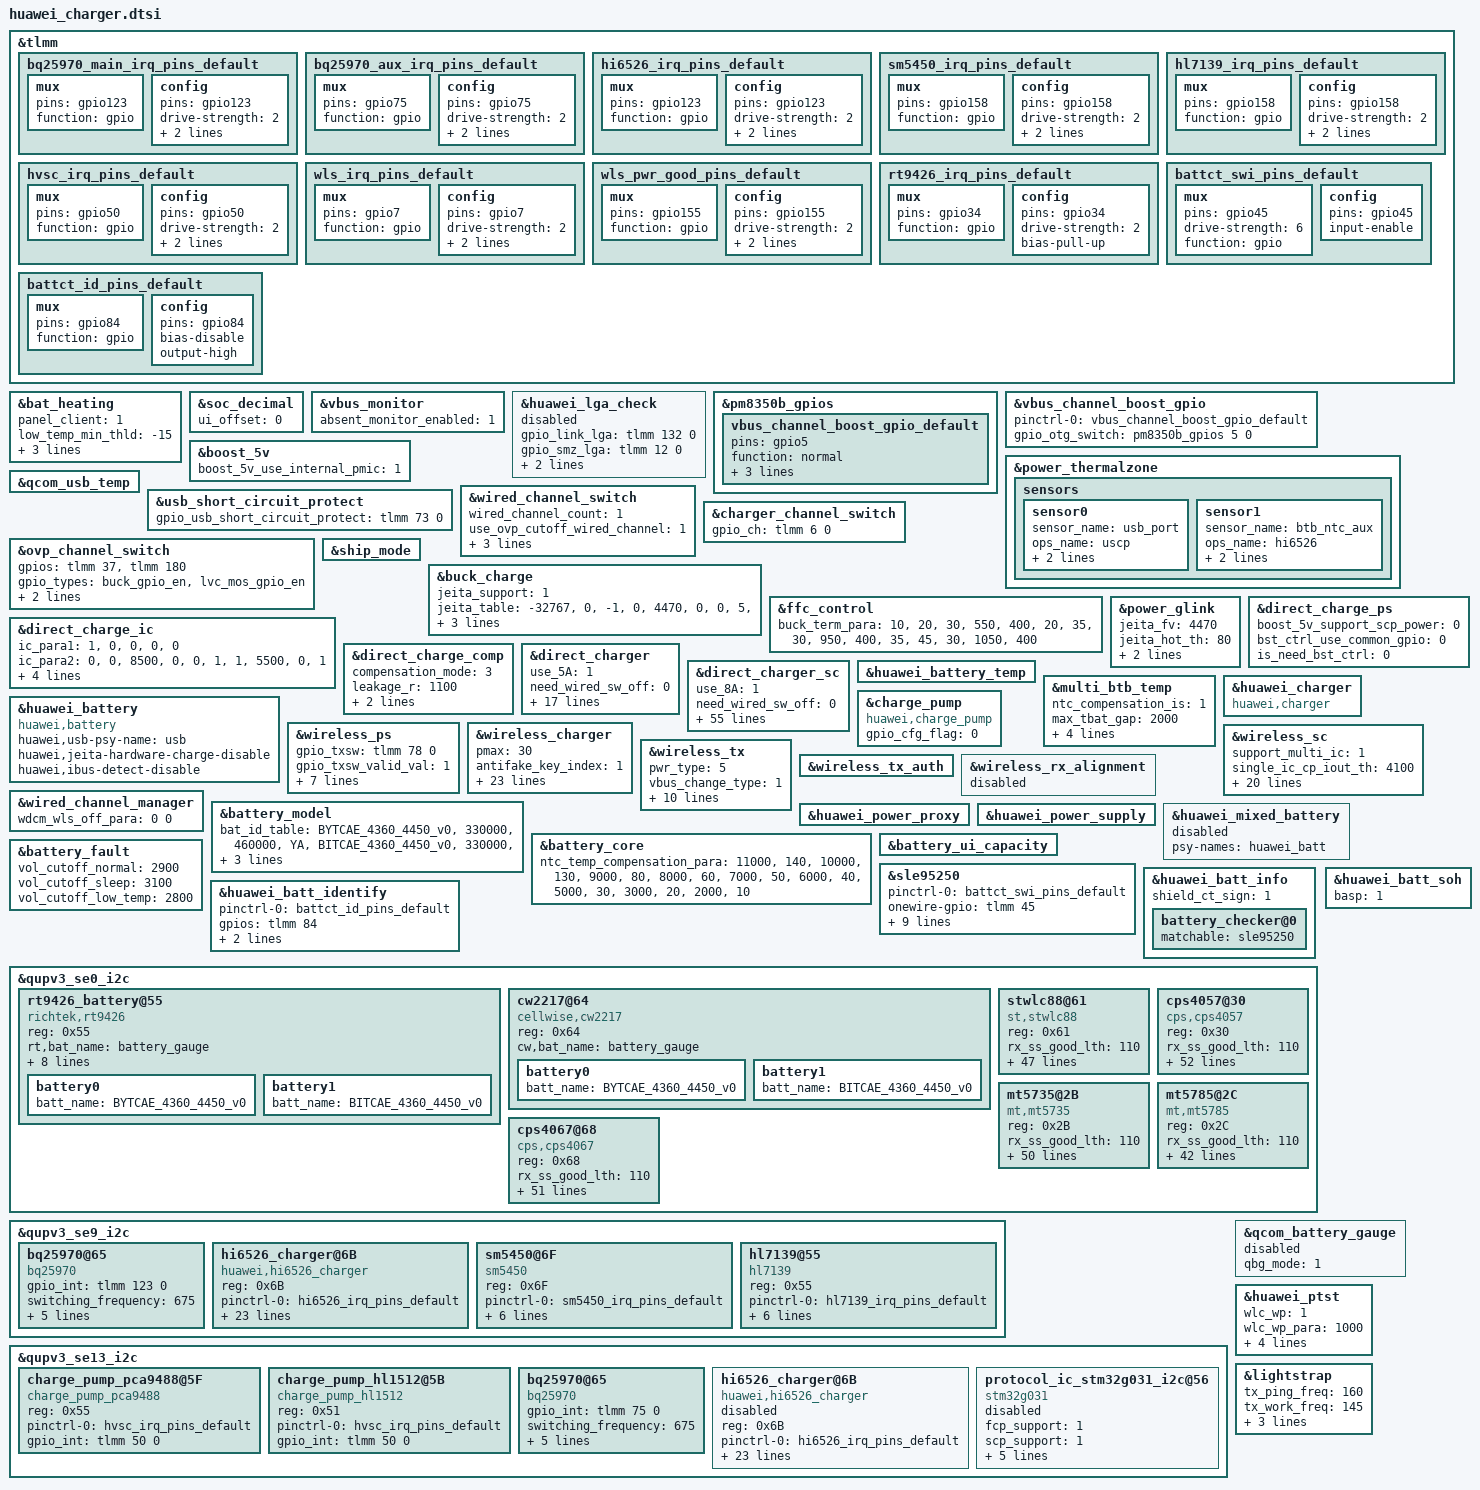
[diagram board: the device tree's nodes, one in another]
&tlmm {
	bq25970_main_irq_pins_default: bq25970_main_irq_pins_default {
		mux {
			pins = "gpio123";
			function = "gpio";
		};
		config {
			pins = "gpio123";
			drive-strength = <2>;
			bias-pull-up;
			input-enable;
		};
	};

	bq25970_aux_irq_pins_default: bq25970_aux_irq_pins_default {
		mux {
			pins = "gpio75";
			function = "gpio";
		};
		config {
			pins = "gpio75";
			drive-strength = <2>;
			bias-pull-up;
			input-enable;
		};
	};

	hi6526_irq_pins_default: hi6526_irq_pins_default {
		mux {
			pins = "gpio123";
			function = "gpio";
		};
		config {
			pins = "gpio123";
			drive-strength = <2>;
			bias-pull-up;
			input-enable;
		};
	};

	sm5450_irq_pins_default: sm5450_irq_pins_default {
		mux {
			pins = "gpio158";
			function = "gpio";
		};
		config {
			pins = "gpio158";
			drive-strength = <2>;
			bias-pull-up;
			input-enable;
		};
	};

	hl7139_irq_pins_default: hl7139_irq_pins_default {
		mux {
			pins = "gpio158";
			function = "gpio";
		};
		config {
			pins = "gpio158";
			drive-strength = <2>;
			bias-pull-up;
			input-enable;
		};
	};

	hvsc_irq_pins_default: hvsc_irq_pins_default {
		mux {
			pins = "gpio50";
			function = "gpio";
		};
		config {
			pins = "gpio50";
			drive-strength = <2>;
			bias-pull-up;
			input-enable;
		};
	};

	wls_irq_pins_default: wls_irq_pins_default {
		mux {
			pins = "gpio7";
			function = "gpio";
		};
		config {
			pins = "gpio7";
			drive-strength = <2>;
			bias-pull-up;
			input-enable;
		};
	};

	wls_pwr_good_pins_default: wls_pwr_good_pins_default {
		mux {
			pins = "gpio155";
			function = "gpio";
		};
		config {
			pins = "gpio155";
			drive-strength = <2>;
			bias-pull-down;
			input-enable;
		};
	};


	rt9426_irq_pins_default: rt9426_irq_pins_default {
		mux {
			pins = "gpio34";
			function = "gpio";
		};
		config {
			pins = "gpio34";
			drive-strength = <2>;
			bias-pull-up;
		};
	};

	battct_swi_pins_default: battct_swi_pins_default {
		mux {
			pins = "gpio45";
			drive-strength = <6>;
			function = "gpio";
		};
		config {
			pins = "gpio45";
			input-enable;
		};
	};

	battct_id_pins_default: battct_id_pins_default {
		mux {
			pins = "gpio84";
			function = "gpio";
		};
		config {
			pins = "gpio84";
			bias-disable;
			output-high;
		};
	};
};

&bat_heating {
	panel_client = "1";
	low_temp_min_thld = "-15";
	low_temp_min_ibat = "-550";
	temp_para =
		"-32767", "0", "0",
		"0", "5", "0",
		"5", "10", "400",
		"10", "20", "2500",
		"20", "45", "4500",
		"45", "32767", "0";
	status = "ok";
};

&soc_decimal {
	ui_offset = <0>;
	status = "ok";
};

&vbus_monitor {
	status = "ok";
	absent_monitor_enabled = <1>;
};

&huawei_lga_check {
	gpio_link_lga = <&tlmm 132 0>; /* GPIO_132 */
	gpio_smz_lga = <&tlmm 12 0>; /* GPIO_012 */
	/* type, name, abnormal_threshold, dmd_no, dmd_switch */
	check_para =
		"2", "gpio_link_lga", "1", "920004103", "1",
		"2", "gpio_smz_lga", "1", "920004103", "1";
	status = "disabled";
};

&pm8350b_gpios {
	vbus_channel_boost_gpio_default: vbus_channel_boost_gpio_default {
		pins = "gpio5";
		function = "normal"; /* normal output */
		bias-disable;
		power-source = <0>; /* VIN0 */
		output-low; /* digital output, no invert */
	};
};

&vbus_channel_boost_gpio {
	pinctrl-names = "vbus_channel_boost_gpio_default";
	pinctrl-0 = <&vbus_channel_boost_gpio_default>;
	gpio_otg_switch = <&pm8350b_gpios 5 0>; /* PM8350B_005 */
	status = "ok";
};

&boost_5v {
	boost_5v_use_internal_pmic = <1>;
	status = "ok";
};

&power_thermalzone {
	status = "ok";
	sensors{
		sensor0 {
			sensor_name = "usb_port";
			ops_name = "uscp";
			adc_channel = <0>;
			ntc_index = <5>;
		};
		sensor1 {
			sensor_name = "btb_ntc_aux";
			ops_name = "hi6526";
			adc_channel = <0>;
			ntc_index = <5>;
		};
	};
};

&qcom_usb_temp {
	status = "ok";
};

&usb_short_circuit_protect {
	gpio_usb_short_circuit_protect = <&tlmm 73 0>; /* GPIO_073 */
	status = "ok";
};

&wired_channel_switch {
	wired_channel_count = <1>;
	use_ovp_cutoff_wired_channel = <1>;
	use_super_switch_cutoff_wired_channel = <0>;
	use_wireless_switch_cutoff_wired_channel = <0>;
	wired_sw_dflt_on = <1>;
	status = "ok";
};

&ovp_channel_switch {
	gpios = <&tlmm 37 0 &tlmm 180 0>;
	gpio_types = "buck_gpio_en", "lvc_mos_gpio_en";
	gpio_en_status = <0 1>;
	gpio_low_by_set_input = <0>;
	status = "ok";
};

&charger_channel_switch {
	gpio_ch = <&tlmm 6 0>; /* GPIO_006 */
	status = "ok";
};

&ship_mode {
	status = "ok";
};

&buck_charge {
	jeita_support = <1>;
	jeita_table =
		"-32767", "0", "-1","0","4470","0",
		"0", "5", "-1", "390", "4470", "0",
		"5", "10", "-1", "1170", "4470", "3",
		"10", "45", "-1", "3000", "4470", "3",
		"45", "50", "-1", "1365", "4100", "3",
		"50", "32767", "-1", "0", "4100", "0";
	status = "ok";
};

&ffc_control {
	status = "ok";
	buck_term_para =
		"10", "20", "30", "550", "400",
		"20", "35", "30", "950", "400",
		"35", "45", "30", "1050", "400";
};

&power_glink {
	jeita_fv = <4470>;
	jeita_hot_th = <80>;
	adsp_jeita_table = <
		0 5 390 4470
		5 10 1170 4470
		10 70 3000 4470
		70 80 1365 4100
	>;
};

&direct_charge_ps {
	boost_5v_support_scp_power = <0>;
	bst_ctrl_use_common_gpio = <0>;
	is_need_bst_ctrl = <0>;
	status = "ok";
};

&direct_charge_ic {
	/* The IC_PARA table is used to find the relationship between chip and path */
	/* the chip's current passing capacity */
	/* and the sampling points of battery voltage and current */
	/* ic_index path_index max_ibat ibat_sample_point vbat_sample_point */
	ic_para1 =
		"1", "0", "0", "0", "0";
	ic_para2 =
		"0", "0", "8500", "0", "0",
		"1", "1", "5500", "0", "1";
	mode_para =
		"lvc_mode", "ic_para1",
		"sc_mode", "ic_para2";
	vbat_en_gpio_output_value = <0>;
	vbat_en_gpio = <&tlmm 98 0>;
	status = "ok";
};

&direct_charge_comp {
	compensation_mode = <3>;
	leakage_r = <1100>;
	compensate_r = <7>;
	/* The vbat_samp_point_para table is used to find the comp relationship between chips */
	/* Calculate all compensation values of the same index */
	/* as the final compensation of the chip */
	/* Separately calculate positive and negative poles */
	/* ic_index  p_index  n_index */
	vbat_samp_point_para =
		"0", "0", "0",
		"1", "1", "1";
	status = "ok";
};

&direct_charger {
	use_5A = <1>;
	need_wired_sw_off = <0>;
	need_check_tx_iin = <1>;
	lvc_mos_para = <1 1600 1500>;
	lvc_mos_err_info = <3 3>;
	volt_para =
		"4080", "5000", "4650",
		"4230", "4650", "2800",
		"4400", "2800", "1200";
	vbat_comp_para =
		"default", "50", "0";
	compensate_r = <0>;
	cc_cable_detect_enable = <1>;
	full_path_res_max = <220>;
	scp_work_on_charger = <1>;
	standard_cable_full_path_res_max = <260>;
	first_cc_stage_timer_in_min = <5>;
	stage_need_to_jump = "1";
	low_temp_hysteresis = <5>;
	temp_para =
		"-32767", "10", "0",
		"10", "45", "5000",
		"45", "32767", "0";
	rt_test_para =
		"2000", "105"; /* rt_curr_th rt_test_time */
	status = "ok";
};

&direct_charger_sc {
	use_8A = <1>;
	need_wired_sw_off = <0>;
	dc_volt_ratio = <2>;
	init_delt_vset = <450>;
	max_adaptor_vset = <11000>;
	init_adapter_vset = <8800>;
	vol_err_th = <500>;
	need_check_tx_iin = <1>;
	adaptor_leakage_current_th = <600>;
	vstep = <20>;
	min_dc_bat_vol = <3450>;
	max_dc_bat_vol = <4380>;
	max_current_for_none_standard_cable = <6000>;
	adaptor_antifake_check_enable = <1>;
	adaptor_antifake_key_index = <2>;
	support_multi_ic = <1>;
	multi_ic_ibat_th = <4000>;
	second_resist_check_en = <1>;
	ui_max_pwr = <40000>;
	product_max_pwr = <66000>;
	volt_para =
		"4150", "8500", "6400",
		"4250", "6400", "5000",
		"4300", "5000", "4200",
		"4460", "4200", "3000",
		"4490", "3000", "900";
	volt_para1 =
		"4200", "12300", "11000",
		"4250", "11000", "8800",
		"4300", "8800", "6800",
		"4460", "6800", "4600",
		"4490", "4600", "1200";
	volt_para2 =
		"4200", "12300", "11000",
		"4250", "11000", "8800",
		"4300", "8800", "6800",
		"4460", "6800", "4600",
		"4490", "4600", "1300";
	time_para =
		"1600", "6650",
		"620", "6850",
		"365", "8000",
		"90", "10000";
	bat_para =
		"default", "10", "20", "volt_para",
		"default", "20", "45", "volt_para1",
		"CAE", "10", "20", "volt_para",
		"CAE", "20", "35", "volt_para1",
		"CAE", "35", "45", "volt_para2";
	vbat_comp_para =
		"default", "45", "0",
		"bq25970", "44", "19",
		"rt9759", "44", "34";
	vstep_para =
		"2000", "80";
	compensate_r = <0>;
	cc_cable_detect_enable = <1>;
	full_path_res_max = <450>;
	scp_work_on_charger = <1>;
	standard_cable_full_path_res_max = <280>;
	first_cc_stage_timer_in_min = <10>;
	stage_need_to_jump = "-1";
	low_temp_hysteresis = <5>;
	current_ratio =
		"3", "10", "25", "2", "-1",
		"3", "13", "22", "1", "8000",
		"0", "13", "22", "0", "0";
	vbat_error =
		"3", "120", "2", "-1",
		"3", "80", "1", "0";
	temp_para =
		"-32767", "10", "0",
		"10", "46", "12800",
		"46", "32767", "0";
	resist_para =
		"0", "260", "6000",
		"260", "450", "4000";
	std_resist_para =
		"0", "300", "0",
		"300", "450", "4000";
	second_resist_para =
		"0", "180", "0",
		"180", "450", "8000";
	ctc_second_resist_para =
		"0", "250", "0",
		"250", "450", "8000";
	rt_test_para =
		/* first:sc second:mainsc third:auxsc */
		"3000", "105",
		"3000", "105",
		"3000", "105";
	status = "ok";
};

&huawei_battery_temp {
	status = "ok";
};

&multi_btb_temp {
	status = "ok";
	ntc_compensation_is = <1>;
	max_tbat_gap = <2000>;
	comp_para =
		"11000", "14000",
		"10000", "13000",
		"9000", "8000",
		"8000", "6000",
		"7000", "5000",
		"6000", "4000",
		"5000", "3000",
		"3000", "2000",
		"2000", "1000";
	sensor-names =
		"battery_gauge", "comp_para";
};

&huawei_battery {
	compatible = "huawei,battery";
	status = "ok";
	huawei,usb-psy-name = "usb";
	huawei,jeita-hardware-charge-disable;
	huawei,ibus-detect-disable;
};

&huawei_charger {
	compatible = "huawei,charger";
	status = "ok";
};

&charge_pump {
	compatible = "huawei,charge_pump";
	gpio_cfg_flag = <0>;
	status = "ok";
};

&wireless_ps {
	gpio_txsw = <&tlmm 78 0>; /* GPIO_078 */
	gpio_txsw_valid_val = <1>;
	gpio_rxsw = <&tlmm 157 0>; /* GPIO_157 */
	gpio_rxsw_valid_val = <0>;
	gpio_ext_pwr_sw = <&tlmm 76 0>; /* GPIO_076 */
	gpio_ext_pwr_sw_valid_val = <1>;
	tx_ps_ctrl_src = <0>; /* 0:NA 1:tx_chip 2:AP */
	sysfs_en_pwr = <1>; /* 0:null 1:rx_pwr 2:tx_pwr */
	proc_otp_pwr = <1>; /* 0:null 1:rx_pwr 2:tx_pwr */
	status = "ok";
};

&wireless_charger {
	pmax = <30>;
	antifake_key_index = <1>;
	ignore_qval = <1>;
	sample_delay_time = <6000>;
	support_high_pwr_wltx = <1>;
	product_max_pwr = <50000>;
	ui_max_pwr = <27000>;
	rx_iout_min = <150>;
	rx_iout_step = <100>;
	rx_iout_ctrl_para = <
		0   100  200
		100 200  300
		200 300  400
		300 400  500
		400 500  600
		500 600  700
		600 700  800
		700 800  900
		800 9999 1100
	>;
	segment_para = <
		999 999 5000 5500 825
	>;
	interference_para =
		"0x01", "0xfe", "131", "5000", "5500", "825",
		"0x02", "0xfd", "-1",  "-1",   "-1",   "1000";
	plim_para =
		"2", "fan", "yes", "12000", "9900", "1250",
		"3", "vout_err", "yes", "12000", "9900", "1250",
		"6", "thermal", "no", "12000", "9900", "1250";
	rx_mode_para =
		/*This table should be arranged in ascending order of power mode priority*/
		/*mode  tx_vout  tx_iout tx_vset  rx_vset  rx_iset vrect_lth tbatt cable cert  icon time expect_mode*/
		"5W",   "5000",  "475",  "5000",  "5500",  "900",  "4650",   "-1", "-1", "-1", "0", "-1",  "4",
		"7.5W", "9000",  "1400", "9000",  "9900",  "900",  "8000",   "-1", "-1", "-1", "0", "-1",  "2",
		"10W",  "9000",  "2000", "9000",  "9900",  "1000", "9000",   "-1", "-1", "1",  "1", "-1",  "4",
		"SC_2", "12000", "2000", "12000", "9000",  "-1",   "-1",     "45", "-1", "1",  "1", "-1",  "4",
		"SC_4", "15000", "1800", "15000", "9000",  "-1",   "-1",     "46", "-1", "1",  "2", "-1",  "-1";
	status = "ok";
};

&wireless_sc {
	support_multi_ic = <1>;
	single_ic_cp_iout_th = <4100>;
	multi_ic_para = <2000 1000 1500 10000>;
	max_vgap = <250>;
	iout_drop_th = <500>;
	tbat_limit_para = <10 13 46 42>;
	init_para_col = <13>; /* must couple with init_para */
	init_para =
		/* in ratio-descending order
		 * ext_pwr: bit(0): needed by sc chip; bit(1): needed by rx
		 * type   type_name ext_pwr rx_ratio vbatt(lth, hth) vrx      vout_th vdiff  ileak_th vdelt  rx_vmax   vtx
		 */
		   "0x2", "SC_2",   "0",   "1",     "3550", "4442", "9000",  "450",  "300", "100",   "300", "10000",  "12000",
		   "0x4", "SC_4",   "2",   "1",     "3550", "4442", "9000",  "500",  "300", "100",   "300", "20000",  "15000";
	volt_para00 =
		"4459", "1300", "600";
	volt_para01 =
		"4150", "4100", "3300",
		"4250", "3300", "2200",
		"4300", "2200", "1500",
		"4420", "1500", "1000";
	volt_para02 =
		"4250", "5100", "4100",
		"4300", "4100", "3200",
		"4380", "3200", "2600",
		"4442", "2600", "1000";
	bat_para =
		"default", "10", "45", "0x02", "volt_para00",
		"default", "10", "45", "0x04", "volt_para01",
		"CAE", "10", "45", "0x02", "volt_para00",
		"CAE", "10", "20", "0x04", "volt_para01",
		"CAE", "20", "45", "0x04", "volt_para02";
	vbat_comp_para =
		"default", "45", "0",
		"bq25970", "44", "19",
		"rt9759", "44", "34";
	status = "ok";
};

&wireless_tx {
	pwr_type = <5>; /* VBUS_OTG2 */
	vbus_change_type = <1>; /* charger plug change */
	tx_iin_limit = <0 0 0 0 0 0 0 0 0 0 0 0>;
	tx_dc_done_buck_ilim = <300>;
	/* rx_vmin rx_vmax tx_vset tx_lvset tx_hvset tx_pl_th tx_pl_cnt */
	tx_vset_para = <
		4000 6400 5000 3500 11000 0 0 0
	>;
	/* power_supply ping handshake default */
	tx_stage_vset = <5000 5000 5000 5000>;
	tx_cap_mode = <0x3>; /* Bit0:2.5W/5W Bit1:7.5W Bit2:XXW */
	tx_high_pwr_soc = <100>;
	tx_high_pwr_ilim = <1600>;
	/* hi_pwr_vth hi_pwr_ith hi_pwr2_vth hi_pwr2_ith */
	wltx_hi_pwr_th = <9000 4000 9000 4000>;
	hs_timeout_offset = <5000>;
	tx_cap = <
		/* type vout iout extra */
		0x9 5000  825  0
		0xA 9000  1400 0
	>;
	status = "ok";
};

&wireless_tx_auth {
	status = "ok";
};

&wireless_rx_alignment {
	status = "disabled";
};

&wired_channel_manager {
	/* channel_state: 0-restore 1-cutoff force_flag */
	wdcm_wls_off_para = <0 0>;
	status = "ok";
};

&battery_model {
	bat_id_table =
		"BYTCAE_4360_4450_v0", "330000", "460000", "YA",
		"BITCAE_4360_4450_v0", "330000", "460000", "IA";
	design_fcc = <4360>;
	id_adc_channel = <0>; /* useless but necessary for Qcom, set 0 as default */
	status = "ok";
};

&huawei_power_proxy {
	status = "ok";
};

&huawei_power_supply {
	 status = "ok";
};

&huawei_mixed_battery {
	psy-names = "huawei_batt";
	status = "disabled";
};

&battery_core {
	ntc_temp_compensation_para =
		"11000", "140",
		"10000", "130",
		"9000", "80",
		"8000", "60",
		"7000", "50",
		"6000", "40",
		"5000", "30",
		"3000", "20",
		"2000", "10";
	status = "ok";
};

&battery_ui_capacity {
	status = "ok";
};

&battery_fault {
	vol_cutoff_normal = <2900>;
	vol_cutoff_sleep = <3100>;
	vol_cutoff_low_temp = <2800>;
	status = "ok";
};

&sle95250 {
	pinctrl-names = "default";
	pinctrl-0 = <&battct_swi_pins_default>;
	onewire-gpio = <&tlmm 45 0>;
	product_id0 = <1>;
	product_id2 = <3>;
	gpio_sn_mode_val = <0>;
	dip_check = <0>;
	gpio_swi = <45>;
	gpio_id_mode = <84>;
	gpio_swi_drv = <2>;
	tau = /bits/ 8 <0xa>;
	tau_fastboot = <7>;
	status = "ok";
};

&huawei_batt_info {
	status = "ok";
	shield_ct_sign = <1>;
	battery_checker@0 {
		matchable = <&sle95250>;
		status = "ok";
	};
};

&huawei_batt_identify {
	pinctrl-names = "default";
	pinctrl-0 = <&battct_id_pins_default>;
	gpios = <&tlmm 84 0>;
	id_voltage_gpiov = <0 1>;
	id_sn_gpiov = <0 0>;
	status = "ok";
};

&qupv3_se0_i2c {
	#address-cells = <1>;
	#size-cells = <0>;
	status = "ok";
	rt9426_battery@55{
		reg = <0x55>;
		compatible = "richtek,rt9426";
		rt,bat_name = "battery_gauge";
		pinctrl-names = "default";
		pinctrl-0 = <&rt9426_irq_pins_default>;
		rt9426,gpio-intb = <&tlmm 34 0x0>;
		need_reset_version = <9>;
		rt_config_ver = <12>;
		ntc_compensation_is = <1>;
		ntc_temp_compensation_para =
			"11000", "140",
			"10000", "130",
			"9000", "80",
			"8000", "60",
			"7000", "50",
			"6000", "40",
			"5000", "30",
			"3000", "20",
			"2000", "10";
		status = "ok";
		battery0{
			batt_name = "BYTCAE_4360_4450_v0";
			#include "../../../huawei_charger/rt9426_BYTCAE_4360mAh_4V45_BT231.dtsi"
		};
		battery1{
			batt_name = "BITCAE_4360_4450_v0";
			#include "../../../huawei_charger/rt9426_BITCAE_4360mAh_4V45_BT231.dtsi"
		};
	};

	cw2217@64 {
		compatible = "cellwise,cw2217";
		reg = <0x64>;
		cw,bat_name = "battery_gauge";
		status = "ok";
		battery0{
			batt_name = "BYTCAE_4360_4450_v0";
			#include "../../../huawei_charger/cw2217_1mohm_BYTCAE_4360mAh_4V45_CET_BT231.dtsi"
		};
		battery1{
			batt_name = "BITCAE_4360_4450_v0";
			#include "../../../huawei_charger/cw2217_1mohm_BITCAE_4360mAh_4V45_CET_BT231.dtsi"
		};
	};

	stwlc88@61 {
		compatible = "st,stwlc88";
		reg = <0x61>;
		rx_ss_good_lth = <110>;
		pinctrl-names = "wls_int", "wls_pwr_good";
		pinctrl-0 = <&wls_irq_pins_default>;
		pinctrl-1 = <&wls_pwr_good_pins_default>;
		gpio_int = <&tlmm 7 0>; /* GPIO_007 */
		gpio_en = <&tlmm 77 0>; /* GPIO_077 */
		gpio_en_valid_val = <0>;
		gpio_sleep_en = <&tlmm 189 0>; /* GPIO_189 */
		gpio_pwr_good = <&tlmm 155 0>; /* GPIO_155 */
		mtp_check_delay = <10000>;
		rx_ldo_cfg_5v = /bits/ 8 <0x13 0x13 0x0D 0x03 0x13 0x20 0x2C>;
		rx_ldo_cfg_9v = /bits/ 8 <0x13 0x13 0x0D 0x03 0x13 0x20 0x2C>;
		rx_ldo_cfg_12v = /bits/ 8 <0x13 0x13 0x0D 0x03 0x13 0x20 0x2C>;
		rx_ldo_cfg_sc = /bits/ 8 <0x2F 0x2F 0x0D 0x03 0x13 0x20 0x2C>;
		rx_ploss_th0 = /bits/ 8 <0x20 0x32 0x4A 0x55 0x64 0x00 0x00 0x00 0x00 0x00 0x00 0x1C 0x1A 0x1A 0x1A 0x1A 0x1A 0x88>;
		rx_ploss_th1 = /bits/ 8 <0x3D 0x65 0x73 0x82 0x96 0x00 0x00 0x00 0xE6 0x00 0x00 0x0C 0x06 0x82 0x82 0xF4 0xF0 0x88>;
		rx_ploss_th2 = /bits/ 8 <0x3D 0x65 0x73 0x82 0x96 0x00 0x00 0x00 0x00 0x00 0x00 0x0C 0x06 0x0C 0xFF 0xF4 0xF0 0x88>;
		rx_ploss_th3 = /bits/ 8 <0x1E 0x3C 0x82 0x00 0x00 0x00 0x00 0x0E 0x21 0x22 0x2B 0x9C 0x00 0x00 0x00 0x00 0x00 0x00>;
		rx_ploss_th4 = /bits/ 8 <0x5A 0x79 0xA8 0xBE 0xFA 0x00 0x00 0x00 0x00 0x00 0x00 0x19 0x3B 0x42 0x13 0xA0 0x87 0x88>;
		rx_fod_cond =
			/* This table should be arranged in descending order of strictness */
			/* id  rx_scn  tx_type  vfc */
			"0", "-1", "-1", "5000",
			"1", "-1", "8", "9000",
			"2", "-1", "-1", "9000",
			"3", "-1", "-1", "12000",
			"4", "-1", "-1", "15000";
		tx_fod_para = /bits/ 8 <0x88 0x13 0x88 0x13 0x88 0x13 0x88 0x13 0x64 0x19 0x64 0x19>;
		tx_fod_cnt = <2>;
		temp_para = <
			/* temp(min,max] ilim temp_back */
			0   100       2500 10
			100 999       1500 0
		>;
		time_para = <
			/* time  ilim */
			840   1275
			540   1375
			240   1520
			85    2200
			0     2500
		>;
		tx_high_vctrl =
			"1000", "115", "48", "17000", "18000", "3000",
			"600",  "120", "48", "16000", "17000", "3000",
			"500",  "140", "40", "17000", "16000", "3000",
			"800",  "140", "40", "18000", "17000", "3000";
		tx_time_alarm =
			"0",   "0", "17000", "18000", "0",
			"330", "1", "8000",  "9000", "0";
		tx_tbatt_alarm =
			"0",  "40", "3", "0", "0",    "0",    "0",
			"40", "42", "3", "1", "8000", "9000", "0",
			"42", "99", "0", "1", "5000", "9000", "0";
		tx_fod_alarm =
			"4", "6400", "8000", "3000", "1", "8000", "9000", "0",
			"5", "7200", "9000", "3000", "1", "8000", "9000", "0";
		status = "ok";
	};

	cps4057@30 {
		compatible = "cps,cps4057";
		reg = <0x30>;
		rx_ss_good_lth = <110>;
		pinctrl-names = "wls_int", "wls_pwr_good";
		pinctrl-0 = <&wls_irq_pins_default>;
		pinctrl-1 = <&wls_pwr_good_pins_default>;
		gpio_int = <&tlmm 7 0>; /* GPIO_007 */
		gpio_en = <&tlmm 77 0>; /* GPIO_077 */
		gpio_en_valid_val = <0>;
		gpio_sleep_en = <&tlmm 189 0>; /* GPIO_189 */
		gpio_pwr_good = <&tlmm 155 0>; /* GPIO_155 */
		full_bridge_ith = <200>;
		mtp_check_delay = <10000>;
		rx_mod_cm_cfg = /bits/ 8 <0x7 0x4 0x6>;
		rx_mod_polar_cfg = /bits/ 8 <0x0 0x0 0x0>;
		rx_ldo_cfg_5v = /bits/ 8 <0x32 0x00 0x90 0x01 0x2C 0x01 0x64 0x00>;
		rx_ldo_cfg_9v = /bits/ 8 <0x32 0x00 0x20 0x03 0x2C 0x01 0x64 0x00>;
		rx_ldo_cfg_sc = /bits/ 8 <0x32 0x00 0x20 0x03 0x2C 0x01 0x64 0x00>;
		rx_ploss_th0 = /bits/ 8 <0x00 0x19 0x32 0x4B 0x64 0x7D 0x96 0xAF 0x50 0x05 0x50 0x05 0x50 0x05 0x50 0x05 0x50 0x05 0x50 0x05 0x50 0x05 0x50 0x05>;
		rx_ploss_th1 = /bits/ 8 <0x00 0x19 0x32 0x4B 0x64 0x7D 0x96 0xAF 0x32 0x0A 0x32 0x0A 0x32 0x0A 0x32 0xC8 0x32 0xC8 0x32 0x0A 0x32 0x0A 0x32 0x0A>;
		rx_ploss_th2 = /bits/ 8 <0x00 0x19 0x32 0x4B 0x64 0x7D 0x96 0xAF 0x32 0x0A 0x32 0x0A 0x32 0x0A 0x32 0x0A 0x32 0x0A 0x32 0x0A 0x32 0x0A 0x32 0x0A>;
		rx_ploss_th3 = /bits/ 8 <0x00 0x19 0x32 0x4B 0x64 0x7D 0x96 0xA0 0x28 0x0A 0x28 0x0A 0x28 0x0A 0x28 0x0A 0x28 0x0A 0x28 0x0A 0x28 0x0A 0x28 0x0A>;
		rx_fod_cond =
			/* This table should be arranged in descending order of strictness */
			/* id  rx_scn  tx_type  vfc */
			"0", "-1", "-1", "5000",
			"1", "-1", "8", "9000",
			"2", "-1", "-1", "9000",
			"3", "-1", "-1", "15000";
		tx_ploss_th0 = <5000>; /* 5v full bridge */
		tx_ploss_th1 = <5000>; /* 10v half bridge */
		tx_ploss_th2 = <1000>; /* 10v full bridge low voltage */
		tx_ploss_th3 = <2000>; /* 10v full bridge high voltage */
		tx_hp_ploss_th0 = <3500>; /* 15v full bridge low current */
		tx_hp_ploss_th1 = <5000>; /* 15v full bridge high current */
		tx_ploss_cnt = <3>;
		tx_q_en = <0>;
		tx_q_coil_th = <105>;
		tx_q_th = <50>;
		temp_para = <
		/* temp(min,max] ilim temp_back */
			0   100       2500 10
			100 999       1500 0
		>;
		time_para = <
			/* time  ilim */
			840   1275
			540   1375
			240   1520
			85    2200
			0     2500
		>;
		tx_high_vctrl =
			"1000", "115", "48", "17000", "18000", "3000",
			"600",  "120", "48", "16000", "17000", "3000",
			"500",  "140", "40", "17000", "16000", "3000",
			"800",  "140", "40", "18000", "17000", "3000";
		tx_time_alarm =
			"0",   "0", "17000", "18000", "0",
			"330", "1", "8000",  "9000", "0";
		tx_tbatt_alarm =
			"0",  "40", "3", "0", "0",    "0",    "0",
			"40", "42", "3", "1", "8000", "9000", "0",
			"42", "99", "0", "1", "5000", "9000", "0";
		tx_fod_alarm =
			"4", "6400", "8000",  "3000", "1", "8000", "9000", "0",
			"5", "8000", "10000", "3000", "1", "8000", "9000", "0";
		status = "ok";
	};

	mt5735@2B {
		compatible = "mt,mt5735";
		reg = <0x2B>;
		rx_ss_good_lth = <110>;
		pinctrl-names = "wls_int", "wls_pwr_good";
		pinctrl-0 = <&wls_irq_pins_default>;
		pinctrl-1 = <&wls_pwr_good_pins_default>;
		gpio_int = <&tlmm 7 0>; /* GPIO_007 */
		gpio_en = <&tlmm 77 0>; /* GPIO_077 */
		gpio_en_valid_val = <0>;
		gpio_sleep_en = <&tlmm 189 0>; /* GPIO_189 */
		gpio_pwr_good = <&tlmm 155 0>; /* GPIO_155 */
		full_bridge_ith = <300>;
		mtp_check_delay = <10000>;
		rx_volt_cap_cfg = /bits/ 8 <0x07 0x0B 0x09>;
		rx_ldo_cfg_5v = /bits/ 8 <0x23 0x00 0x19 0x00 0x20 0x03 0x46 0x00>;
		rx_ldo_cfg_9v = /bits/ 8 <0x17 0x00 0x14 0x00 0xe8 0x03 0x64 0x00>;
		rx_ldo_cfg_12v = /bits/ 8 <0x17 0x00 0x14 0x00 0xe8 0x03 0x64 0x00>;
		rx_ldo_cfg_sc = /bits/ 8 <0x17 0x00 0x14 0x00 0xe8 0x03 0x64 0x00>;
		rx_ploss_th0 = /bits/ 8 <0x00 0x46 0x00 0x3A 0x00 0x37 0x00 0x46 0x00 0x50 0x00 0x62 0x00 0x72 0x00 0x72>;
		rx_ploss_th1 = /bits/ 8 <0x00 0x7F 0x00 0x7F 0x00 0x7F 0x00 0x64 0x64 0x64 0x64 0x64 0x5A 0x7F 0x5A 0x7F>;
		rx_ploss_th2 = /bits/ 8 <0x00 0x7F 0x00 0x7F 0x00 0x7F 0x00 0x64 0x64 0x64 0x64 0x64 0x5A 0x7F 0x5A 0x7F>;
		rx_ploss_th3 = /bits/ 8 <0x00 0x50 0x00 0x7F 0x28 0x7F 0x58 0x7F 0x2D 0x7F 0x32 0x00 0x37 0x7F 0x37 0x7F>;
		rx_fod_cond =
			/* This table should be arranged in descending order of strictness */
			/* id  rx_scn  tx_type  vfc */
			"0", "-1", "-1", "5000",
			"1", "-1", "8", "9000",
			"2", "-1", "-1", "9000",
			"3", "-1", "-1", "15000";
		tx_ploss_th0 = <5000>; /* 5v full bridge */
		tx_ploss_th1 = <5000>; /* 10v half bridge */
		tx_ploss_th2 = <5000>; /* 10v full bridge low voltage */
		tx_ploss_th3 = <5000>; /* 10v full bridge high voltage */
		tx_hp_ploss_th0 = <4000>; /* 15v full bridge low current */
		tx_hp_ploss_th1 = <5000>; /* 15v full bridge high current */
		tx_ploss_cnt = <3>;
		temp_para = <
			/* temp(min,max] ilim temp_back */
			0   100       2500 10
			100 999       1500 0
		>;
		time_para = <
			/* time  ilim */
			840   1275
			540   1375
			240   1520
			85    2200
			0     2500
		>;
		tx_high_vctrl =
			"600", "115", "48", "17000", "19000", "3000",
			"500", "120", "48", "16000", "17000", "3000",
			"500", "140", "40", "17000", "16000", "3000",
			"800", "140", "40", "19000", "17000", "3000";
		tx_time_alarm =
			"0",   "0", "17000", "18000", "0",
			"330", "1", "8000",  "9000", "0";
		tx_tbatt_alarm =
			"0",  "40", "3", "0", "0",    "0",    "0",
			"40", "42", "3", "1", "8000", "9000", "0",
			"42", "99", "0", "1", "5000", "9000", "0";
		tx_fod_alarm =
			"4", "6400", "8000", "3000", "1", "8000", "9000", "0",
			"5", "7200", "9000", "3000", "1", "8000", "9000", "0";
		status = "ok";
	};

	mt5785@2C {
		compatible = "mt,mt5785";
		reg = <0x2C>;
		rx_ss_good_lth = <110>;
		pinctrl-names = "wls_int", "wls_pwr_good";
		pinctrl-0 = <&wls_irq_pins_default>;
		pinctrl-1 = <&wls_pwr_good_pins_default>;
		gpio_int = <&tlmm 7 0>; /* GPIO_007 */
		gpio_en = <&tlmm 77 0>; /* GPIO_077 */
		gpio_en_valid_val = <0>;
		gpio_sleep_en = <&tlmm 189 0>; /* GPIO_189 */
		gpio_pwr_good = <&tlmm 155 0>; /* GPIO_155 */
		mtp_check_delay = <10000>;
		rx_mod_cm_cfg = /bits/ 8 <0x3 0x3 0x3>;
		rx_mod_polar_cfg = /bits/ 8 <0x0 0x0 0x0>;
		rx_ldo_cfg_5v = /bits/ 8 <0x32 0x00 0x20 0x03 0x64 0x00 0x2C 0x01>;
		rx_ldo_cfg_9v = /bits/ 8 <0x32 0x00 0x20 0x03 0x64 0x00 0x2C 0x01>;
		rx_ldo_cfg_sc = /bits/ 8 <0x32 0x00 0xDC 0x05 0x64 0x00 0x2C 0x01>;
		rx_fod_5v = /bits/ 8 <0x19 0x32 0x4B 0x64 0x7D 0x96 0xAF 0x50 0x05 0x50 0x05 0x50 0x05 0x50 0x05 0x50 0x05 0x50 0x05 0x50 0x05 0x50 0x05>;
		rx_fod_9v = /bits/ 8 <0x19 0x32 0x4B 0x64 0x7D 0x96 0xAF 0x32 0x0A 0x32 0x0A 0x32 0x0A 0x32 0x0A 0x32 0x0A 0x32 0x0A 0x32 0x0A 0x32 0x0A>;
		rx_fod_15v = /bits/ 8 <0x19 0x32 0x4B 0x64 0x7D 0x96 0xA0 0x28 0x0A 0x28 0x0A 0x28 0x0A 0x28 0x0A 0x28 0x0A 0x28 0x0A 0x28 0x0A 0x28 0x0A>;
		rx_fod_9v_cp39s_hk = /bits/ 8 <0x19 0x32 0x4B 0x64 0x7D 0x96 0xAF 0x32 0x0A 0x32 0x0A 0x32 0x0A 0x32 0xC8 0x32 0xC8 0x32 0x0A 0x32 0x0A 0x32 0x0A>;
		tx_ploss_th0 = <5000>; /* 5v full bridge */
		tx_ploss_th1 = <5000>; /* 10v half bridge */
		tx_ploss_th2 = <1000>; /* 10v full bridge low voltage */
		tx_ploss_th3 = <2000>; /* 10v full bridge high voltage */
		tx_hp_ploss_th0 = <3500>; /* 15v full bridge low current */
		tx_hp_ploss_th1 = <5000>; /* 15v full bridge high current */
		tx_ploss_cnt = <3>;
		tx_q_en = <0>;
		tx_q_coil_th = <105>;
		tx_q_th = <50>;
		temp_para = <
		/* temp(min,max] ilim temp_back */
			0   100       5000 10
			100 999       3000 0
		>;
		time_para = <
			/* time  ilim */
			840   2550
			540   2750
			240   3040
			85    4400
			0     5000
		>;
		tx_time_alarm =
			"0",   "0", "17000", "18000", "0",
			"330", "1", "8000",  "9000", "0";
		tx_tbatt_alarm =
			"0",  "40", "3", "0", "0",    "0",    "0",
			"40", "42", "3", "1", "8000", "9000", "0",
			"42", "99", "0", "1", "5000", "9000", "0";
		status = "ok";
	};

	cps4067@68 {
		compatible = "cps,cps4067";
		reg = <0x68>;
		rx_ss_good_lth = <110>;
		pinctrl-names = "wls_int", "wls_pwr_good";
		pinctrl-0 = <&wls_irq_pins_default>;
		pinctrl-1 = <&wls_pwr_good_pins_default>;
		gpio_int = <&tlmm 7 0>; /* GPIO_007 */
		gpio_en = <&tlmm 77 0>; /* GPIO_077 */
		gpio_en_valid_val = <0>;
		gpio_sleep_en = <&tlmm 189 0>; /* GPIO_189 */
		gpio_pwr_good = <&tlmm 155 0>; /* GPIO_155 */
		full_bridge_ith = <200>;
		mtp_check_delay = <10000>;
		rx_mod_cm_cfg = /bits/ 8 <0x7 0x3 0x3>;
		rx_mod_polar_cfg = /bits/ 8 <0x0 0x0 0x0>;
		rx_ldo_cfg_5v = /bits/ 8 <0x32 0x00 0x20 0x03 0x64 0x00 0x2C 0x01>;
		rx_ldo_cfg_9v = /bits/ 8 <0x32 0x00 0x20 0x03 0x64 0x00 0x2C 0x01>;
		rx_ldo_cfg_sc = /bits/ 8 <0x32 0x00 0xDC 0x05 0x64 0x00 0x2C 0x01>;
		rx_fod_5v = /bits/ 8 <0x19 0x32 0x4B 0x64 0x7D 0x96 0xAF 0x50 0x05 0x50 0x05 0x50 0x05 0x50 0x05 0x50 0x05 0x50 0x05 0x50 0x05 0x50 0x05>;
		rx_fod_9v = /bits/ 8 <0x19 0x32 0x4B 0x64 0x7D 0x96 0xAF 0x32 0x0A 0x32 0x0A 0x32 0x0A 0x32 0x0A 0x32 0x0A 0x32 0x0A 0x32 0x0A 0x32 0x0A>;
		rx_fod_15v = /bits/ 8 <0x19 0x32 0x4B 0x64 0x7D 0x96 0xA0 0x28 0x0A 0x28 0x0A 0x28 0x0A 0x28 0x0A 0x28 0x0A 0x28 0x0A 0x28 0x0A 0x28 0x0A>;
		rx_fod_9v_cp39s_hk = /bits/ 8 <0x19 0x32 0x4B 0x64 0x7D 0x96 0xAF 0x32 0x0A 0x32 0x0A 0x32 0x0A 0x32 0xC8 0x32 0xC8 0x32 0x0A 0x32 0x0A 0x32 0x0A>;
		tx_ploss_th0 = <5000>; /* 5v full bridge */
		tx_ploss_th1 = <5000>; /* 10v half bridge */
		tx_ploss_th2 = <1000>; /* 10v full bridge low voltage */
		tx_ploss_th3 = <2000>; /* 10v full bridge high voltage */
		tx_hp_ploss_th0 = <3500>; /* 15v full bridge low current */
		tx_hp_ploss_th1 = <5000>; /* 15v full bridge high current */
		tx_ploss_cnt = <3>;
		tx_q_en = <0>;
		tx_q_coil_th = <105>;
		tx_q_th = <50>;
		temp_para = <
		/* temp(min,max] ilim temp_back */
			0   100       5000 10
			100 999       3000 0
		>;
		time_para = <
			/* time  ilim */
			840   2550
			540   2750
			180   3040
			85    4400
			0     5000
		>;
		tx_high_vctrl =
			"1000", "115", "48", "17000", "18000", "3000",
			"600",  "120", "48", "16000", "17000", "3000",
			"500",  "140", "40", "17000", "16000", "3000",
			"800",  "140", "40", "18000", "17000", "3000";
		tx_time_alarm =
			"0",   "0", "17000", "18000", "0",
			"330", "1", "8000",  "9000", "0";
		tx_tbatt_alarm_all = <1>;
		tx_tbatt_alarm =
			"0",  "40", "3", "0", "0",    "0",    "0",
			"40", "42", "3", "1", "8000", "9000", "0",
			"42", "99", "0", "1", "3000", "5000", "0";
		tx_fod_alarm =
			"4", "6400", "8000",  "3000", "1", "8000", "9000", "0",
			"5", "8000", "10000", "3000", "1", "8000", "9000", "0";
		status = "ok";
	};
};

&qupv3_se9_i2c {
	#address-cells = <1>;
	#size-cells = <0>;
	status = "ok";

	bq25970@65 {
		compatible = "bq25970";
		gpio_int = <&tlmm 123 0>;
		switching_frequency = <675>;
		reg = <0x65>;
		pinctrl-names = "default";
		pinctrl-0 = <&bq25970_main_irq_pins_default>;
		ic_role = <0>;
		sense_r_actual = <10>;
		resume_need_wait_i2c = <1>;
		status = "ok";
	};

	hi6526_charger@6B {
		status = "ok";
		compatible = "huawei,hi6526_charger";
		reg = <0x6B>;
		pinctrl-names = "hi6526_irq_pins_default";
		pinctrl-0 = <&hi6526_irq_pins_default>;
		intr_gpio_num = <123>;
		intr_gpio = <&tlmm 123 0>;
		rst_gpio = <&tlmm 36 0>;
		bat_comp = <15>;
		vclamp = <150>;
		adc_channel_vbat_sys = <14>;
		fcp_support = <0>;
		scp_support = <0>;
		lvc_ibat_regulator = <12200>;
		lvc_vbat_regulator = <4500>;
		lvc_vout_regulator = <4550>;
		lvc_ibus_regulator = <5600>;
		sc_ibat_regulator = <12200>;
		sc_vbat_regulator = <4500>;
		sc_vout_regulator = <4590>;
		sc_ibus_regulator = <5600>;
		lvc_vusb2vbus_drop_en = <1>;
		sc_vusb2vbus_drop_en = <1>;
		/* loop mode must be turned off, if temperature channels need to be acquired */
		adc_single_mode_en = <0>;
		adc_tsbat_support = <0>;
		ico_current_mode = <0>;
		r_coul_mohm = <1>;
		vusb_uv_flag = <1>;
	};

	sm5450@6F{
		compatible = "sm5450";
		reg = <0x6F>;
		pinctrl-names = "default";
		pinctrl-0 = <&sm5450_irq_pins_default>;
		intr_gpio_num = <158>; /* direct defined GPIO num */
		intr_gpio = <&tlmm 158 0>;
		fcp_support = <1>;
		scp_support = <1>;
		sense_r_actual = <10>;
		ic_role = <1>;
		status = "ok";
	};

	hl7139@55{
		compatible = "hl7139";
		reg = <0x55>;
		pinctrl-names = "default";
		pinctrl-0 = <&hl7139_irq_pins_default>;
		intr_gpio_num = <158>; /* direct defined GPIO num */
		intr_gpio = <&tlmm 158 0>;
		fcp_support = <1>;
		scp_support = <1>;
		sense_r_actual = <10>;
		ic_role = <1>;
		status = "ok";
	};
};

&huawei_batt_soh {
	basp = <1>;
	status = "ok";
};

&qupv3_se13_i2c {
	#address-cells = <1>;
	#size-cells = <0>;
	status = "ok";
	charge_pump_pca9488@5F {
		compatible = "charge_pump_pca9488";
		reg = <0x55>;
		pinctrl-names = "hvsc_irq_pins_default";
		pinctrl-0 = <&hvsc_irq_pins_default>;
		gpio_int = <&tlmm 50 0>;
		status = "ok";
	};

	charge_pump_hl1512@5B {
		compatible = "charge_pump_hl1512";
		reg = <0x51>;
		pinctrl-names = "hvsc_irq_pins_default";
		pinctrl-0 = <&hvsc_irq_pins_default>;
		gpio_int = <&tlmm 50 0>;
		status = "ok";
	};

	bq25970@65 {
		compatible = "bq25970";
		gpio_int = <&tlmm 75 0>;
		switching_frequency = <675>;
		reg = <0x65>;
		pinctrl-names = "default";
		pinctrl-0 = <&bq25970_aux_irq_pins_default>;
		ic_role = <1>;
		sense_r_actual = <10>;
		resume_need_wait_i2c = <1>;
		status = "ok";
	};

	hi6526_charger@6B {
		status = "disabled";
		compatible = "huawei,hi6526_charger";
		reg = <0x6B>;
		pinctrl-names = "hi6526_irq_pins_default";
		pinctrl-0 = <&hi6526_irq_pins_default>;
		intr_gpio_num = <123>;
		intr_gpio = <&tlmm 123 0>;
		rst_gpio = <&tlmm 36 0>;
		bat_comp = <15>;
		vclamp = <150>;
		adc_channel_vbat_sys = <14>;
		fcp_support = <1>;
		scp_support = <1>;
		lvc_ibat_regulator = <12200>;
		lvc_vbat_regulator = <4500>;
		lvc_vout_regulator = <4550>;
		lvc_ibus_regulator = <5600>;
		sc_ibat_regulator = <12200>;
		sc_vbat_regulator = <4500>;
		sc_vout_regulator = <4590>;
		sc_ibus_regulator = <5600>;
		lvc_vusb2vbus_drop_en = <1>;
		sc_vusb2vbus_drop_en = <1>;
		/* loop mode must be turned off, if temperature channels need to be acquired */
		adc_single_mode_en = <0>;
		adc_tsbat_support = <0>;
		ico_current_mode = <0>;
		r_coul_mohm = <1>;
		vusb_uv_flag = <1>;
	};

	protocol_ic_stm32g031_i2c@56 {
		compatible = "stm32g031";
		fcp_support = <1>;
		scp_support = <1>;
		wait_time = <20>;
		gpio_enable = <&tlmm 35 0>;
		gpio_reset = <&tlmm 79 0>;
		gpio_int = <&tlmm 31 0>;
		reg = <0x56>;
		status = "disabled";
	};
};

&qcom_battery_gauge {
	qbg_mode = <1>;
	status = "disabled";
};

&huawei_ptst {
	wlc_wp = <1>;
	wlc_wp_para = <1000>;
	wl_hw_test = <1>;
	wl_hw_module = <0x1>;
	wlc_mmi = <1>;
	wlc_mmi_para = <40 0x07 2 2000 15000 0>;
	status = "ok";
};

&lightstrap {
	tx_ping_freq = <160>;
	tx_work_freq = <145>;
	retry_times = <4>;
	wltx_pwr_src = <2>; /* otg power */
	model_id = "29LI";
	status = "ok";
};
